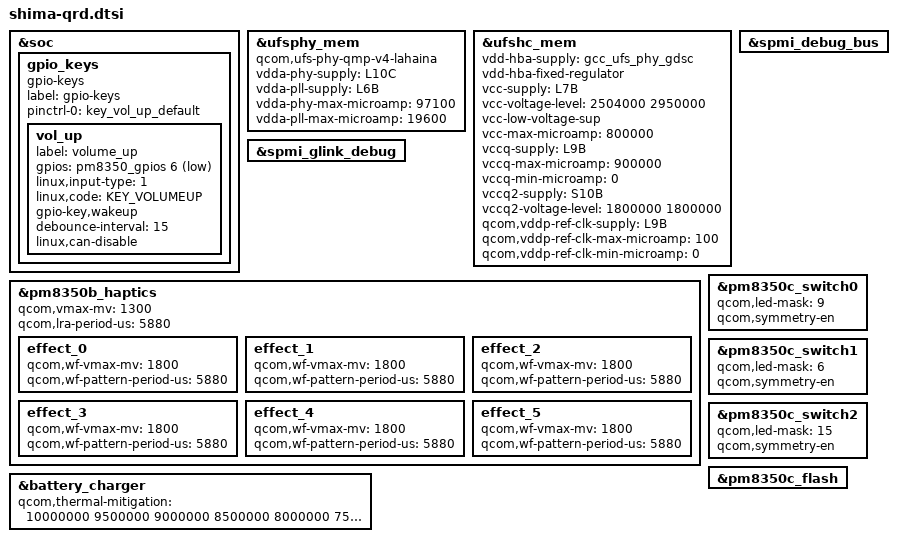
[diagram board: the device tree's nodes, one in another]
#include <dt-bindings/gpio/gpio.h>
#include <dt-bindings/input/input.h>
#include "shima-pmic-overlay.dtsi"

&soc {
	gpio_keys {
		compatible = "gpio-keys";
		label = "gpio-keys";

		pinctrl-names = "default";
		pinctrl-0 = <&key_vol_up_default>;

		vol_up {
			label = "volume_up";
			gpios = <&pm8350_gpios 6 GPIO_ACTIVE_LOW>;
			linux,input-type = <1>;
			linux,code = <KEY_VOLUMEUP>;
			gpio-key,wakeup;
			debounce-interval = <15>;
			linux,can-disable;
		};
	};
};

&ufsphy_mem {
	compatible = "qcom,ufs-phy-qmp-v4-lahaina";

	vdda-phy-supply = <&L10C>;
	vdda-pll-supply = <&L6B>;
	vdda-phy-max-microamp = <97100>;
	vdda-pll-max-microamp = <19600>;

	status = "ok";
};

&ufshc_mem {
	vdd-hba-supply = <&gcc_ufs_phy_gdsc>;
	vdd-hba-fixed-regulator;

	vcc-supply = <&L7B>;
	vcc-voltage-level = <2504000 2950000>;
	vcc-low-voltage-sup;
	vcc-max-microamp = <800000>;

	vccq-supply = <&L9B>;
	vccq-max-microamp = <900000>;
	vccq-min-microamp = <0>;

	vccq2-supply = <&S10B>;
	vccq2-voltage-level = <1800000 1800000>;

	qcom,vddp-ref-clk-supply = <&L9B>;
	qcom,vddp-ref-clk-max-microamp = <100>;
	qcom,vddp-ref-clk-min-microamp = <0>;
	status = "ok";
};

&spmi_debug_bus {
	status = "ok";
};

&spmi_glink_debug {
	status = "ok";
};

&pm8350b_haptics {
	qcom,vmax-mv = <1300>;
	qcom,lra-period-us = <5880>;
	status = "ok";

	effect_0 {
		/* CLICK */
		qcom,wf-vmax-mv = <1800>;
		qcom,wf-pattern-period-us = <5880>;
	};

	effect_1 {
		/* DOUBLE_CLICK */
		qcom,wf-vmax-mv = <1800>;
		qcom,wf-pattern-period-us = <5880>;
	};

	effect_2 {
		/* TICK */
		qcom,wf-vmax-mv = <1800>;
		qcom,wf-pattern-period-us = <5880>;
	};

	effect_3 {
		/* THUD */
		qcom,wf-vmax-mv = <1800>;
		qcom,wf-pattern-period-us = <5880>;
	};

	effect_4 {
		/* POP */
		qcom,wf-vmax-mv = <1800>;
		qcom,wf-pattern-period-us = <5880>;
	};

	effect_5 {
		/* HEAVY CLICK */
		qcom,wf-vmax-mv = <1800>;
		qcom,wf-pattern-period-us = <5880>;
	};
};

&pm8350c_switch0 {
	qcom,led-mask = <9>; /* Channels 1 & 4 */
	qcom,symmetry-en;
};

&pm8350c_switch1 {
	qcom,led-mask = <6>; /* Channels 2 & 3 */
	qcom,symmetry-en;
};

&pm8350c_switch2 {
	qcom,led-mask = <15>; /* All Channels */
	qcom,symmetry-en;
};

&pm8350c_flash {
	status = "ok";
};

&battery_charger {
	qcom,thermal-mitigation = <10000000 9500000 9000000 8500000 8000000
				7500000 7000000 6500000 6000000 5500000
				5000000 4500000 4000000 3500000 3000000
				2500000 2000000 1500000 1000000 500000>;
};
